# SERCOSIII register map
Registers from a debugger description file.
Registers are 32-bit, access not given, no defined reset value unless marked. A register's access mark holds for its fields unless they carry their own. Addresses are absolute; registers are grouped by the start of their names; lines under a group give offsets from that group; [hi:lo] are bit positions; {n}, {i} and the like mark numbered series; 'fields as' and 'values as' point back to an identical list; <NAME> marks a mode.

## MAC1P1
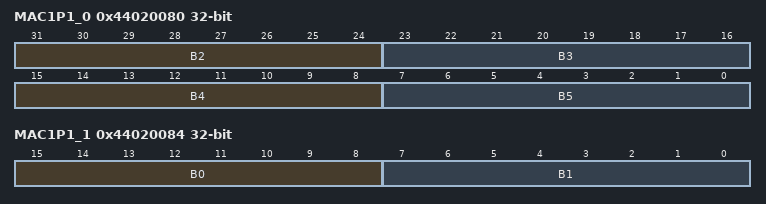
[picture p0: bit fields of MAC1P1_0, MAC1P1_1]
0x44020080 MAC1P1_0
  [47-8n:40-8n] B{n} (n=2..5)
0x44020084 MAC1P1_1
  [15:8] B0, [7:0] B1

## RXBUF0
0x44020180 RXBUF0_P1A
0x44020190 RXBUF0_P1B
0x440201A0 RXBUF0_P2A
0x440201B0 RXBUF0_P2B

## RXBUF1
0x44020184 RXBUF1_P1A
0x44020194 RXBUF1_P1B
0x440201A4 RXBUF1_P2A
0x440201B4 RXBUF1_P2B

## RXBUF2
0x44020188 RXBUF2_P1A
0x44020198 RXBUF2_P1B
0x440201A8 RXBUF2_P2A
0x440201B8 RXBUF2_P2B

## RXBUF
0x4402019C RXBUF_P1SVC
0x440201BC RXBUF_P2SVC

## TXBUF0
0x440201C0 TXBUF0_A
0x440201D0 TXBUF0_B

## TXBUF1
0x440201C4 TXBUF1_A
0x440201D4 TXBUF1_B

## TXBUF2
0x440201C8 TXBUF2_A
0x440201D8 TXBUF2_B

## TXBUF3
0x440201CC TXBUF3_A
0x440201DC TXBUF3_B

## TXBUF
0x440201F0 TXBUF_P1
0x440201F4 TXBUF_P2
0x440201FC TXBUF_SVC

## RXBUFCSR
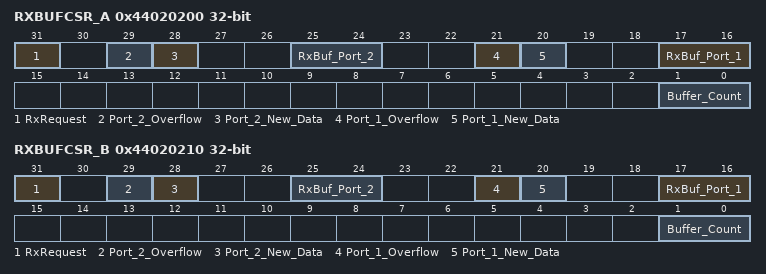
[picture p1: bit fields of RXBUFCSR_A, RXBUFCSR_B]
0x44020200 RXBUFCSR_A
  [31] RxRequest, [29] Port_2_Overflow ro, [28] Port_2_New_Data ro, [25:24] RxBuf_Port_2 ro, [21] Port_1_Overflow ro, [20] Port_1_New_Data ro, [17:16] RxBuf_Port_1 ro, [1:0] Buffer_Count
0x44020210 RXBUFCSR_B
  fields as RXBUFCSR_A

## RXBUFTV
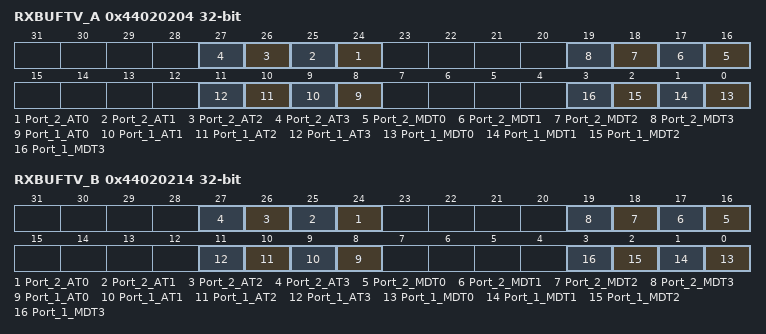
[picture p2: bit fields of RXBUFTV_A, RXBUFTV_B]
0x44020204 RXBUFTV_A ro
  [n+24] Port_2_AT{n} (n=0..3), [n+16] Port_2_MDT{n} (n=0..3), [n+8] Port_1_AT{n} (n=0..3), [n] Port_1_MDT{n} (n=0..3)
0x44020214 RXBUFTV_B ro
  fields as RXBUFTV_A

## RXBUFTR
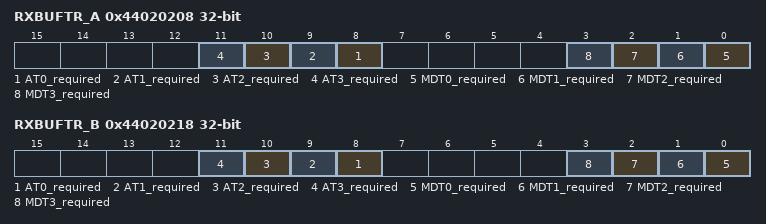
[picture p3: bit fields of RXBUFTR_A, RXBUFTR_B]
0x44020208 RXBUFTR_A
  [n+8] AT{n}_required (n=0..3), [n] MDT{n}_required (n=0..3)
0x44020218 RXBUFTR_B
  [n+8] AT{n}_required (n=0..3), [n] MDT{n}_required (n=0..3)

## TXBUFCSR
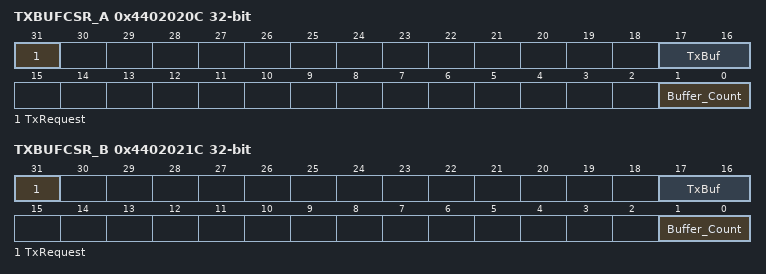
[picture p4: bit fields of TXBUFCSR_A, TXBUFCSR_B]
0x4402020C TXBUFCSR_A
  [31] TxRequest, [17:16] TxBuf, [1:0] Buffer_Count
0x4402021C TXBUFCSR_B
  [31] TxRequest, [17:16] TxBuf, [1:0] Buffer_Count
